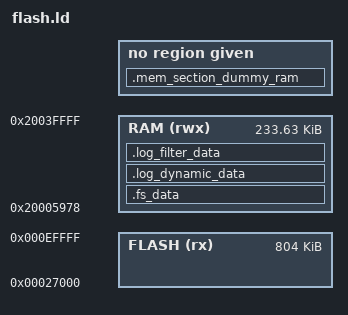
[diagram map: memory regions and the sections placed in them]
/* Linker script to configure memory regions. */

SEARCH_DIR(.)
GROUP(-lgcc -lc -lnosys)

/* 
  FLASH:
    ORIGIN = 0x27000
      The softdevice is located between addresses 0 and 0x27000 - 1 so 
      memory app starts at 0x27000.
    
    LENGTH = 0xC9000
      Total length of the app firmware, excluding the softdevice.
      Following are the 3 reserved pages for FDS ans 2 pages for the EEPROM class.
      The last 9 pages of flash are for the bootloader, the MBR and bootloader
      data storage.

  RAM:
    ORIGIN = 0x20009400
      The RAM memory starts at 0x20000000 and has a length of 0x40000 (256 KB), 
      but the softdevice uses the first 0x5978 Bytes.

    LENGTH = 0x16C00
      0x20000 - 0x9400 Bytes for the softdevice = 0x16C00 Bytes.
*/
MEMORY
{  
  FLASH (rx) : ORIGIN = 0x27000, LENGTH = 0xC9000
  /*FLASH (rx) : ORIGIN = 0x27000, LENGTH = 0xD4000       /* No bootloader */
  RAM (rwx) :  ORIGIN = 0x20005978, LENGTH = 0x3A688      /* s140 */  
}

SECTIONS
{
  . = ALIGN(4);
  .mem_section_dummy_ram :
  {
  }

  /* Memory section for FDS library. */
  .fs_data :
  {
    PROVIDE(__start_fs_data = .);
    KEEP(*(.fs_data))
    PROVIDE(__stop_fs_data = .);
  } > RAM

  .log_dynamic_data :
  {
    PROVIDE(__start_log_dynamic_data = .);
    KEEP(*(SORT(.log_dynamic_data*)))
    PROVIDE(__stop_log_dynamic_data = .);
  } > RAM

  .log_filter_data :
  {
    PROVIDE(__start_log_filter_data = .);
    KEEP(*(SORT(.log_filter_data*)))
    PROVIDE(__stop_log_filter_data = .);
  } > RAM
} INSERT AFTER .data;

SECTIONS
{
  .mem_section_dummy_rom :
  {
  }

  .sdh_ble_observers :
  {
    PROVIDE(__start_sdh_ble_observers = .);
    KEEP(*(SORT(.sdh_ble_observers*)))
    PROVIDE(__stop_sdh_ble_observers = .);
  } > FLASH

  .svc_data :
  {
    PROVIDE(__start_svc_data = .);
    KEEP(*(.svc_data))
    PROVIDE(__stop_svc_data = .);
  } > FLASH
  
  .sdh_req_observers :
  {
    PROVIDE(__start_sdh_req_observers = .);
    KEEP(*(SORT(.sdh_req_observers*)))
    PROVIDE(__stop_sdh_req_observers = .);
  } > FLASH

  .sdh_state_observers :
  {
    PROVIDE(__start_sdh_state_observers = .);
    KEEP(*(SORT(.sdh_state_observers*)))
    PROVIDE(__stop_sdh_state_observers = .);
  } > FLASH

  .sdh_stack_observers :
  {
    PROVIDE(__start_sdh_stack_observers = .);
    KEEP(*(SORT(.sdh_stack_observers*)))
    PROVIDE(__stop_sdh_stack_observers = .);
  } > FLASH

  .sdh_soc_observers :
  {
    PROVIDE(__start_sdh_soc_observers = .);
    KEEP(*(SORT(.sdh_soc_observers*)))
    PROVIDE(__stop_sdh_soc_observers = .);
  } > FLASH

  .pwr_mgmt_data :
  {
    PROVIDE(__start_pwr_mgmt_data = .);
    KEEP(*(SORT(.pwr_mgmt_data*)))
    PROVIDE(__stop_pwr_mgmt_data = .);
  } > FLASH

  .nrf_queue :
  {
    PROVIDE(__start_nrf_queue = .);
    KEEP(*(.nrf_queue))
    PROVIDE(__stop_nrf_queue = .);
  } > FLASH

  .nrf_balloc :
  {
    PROVIDE(__start_nrf_balloc = .);
    KEEP(*(.nrf_balloc))
    PROVIDE(__stop_nrf_balloc = .);
  } > FLASH

  .crypto_data :
  {
    PROVIDE(__start_crypto_data = .);
    KEEP(*(SORT(.crypto_data*)))
    PROVIDE(__stop_crypto_data = .);
  } > FLASH

  .log_const_data :
  {
    PROVIDE(__start_log_const_data = .);
    KEEP(*(SORT(.log_const_data*)))
    PROVIDE(__stop_log_const_data = .);
  } > FLASH
} INSERT AFTER .text

INCLUDE "nrf_common.ld"
